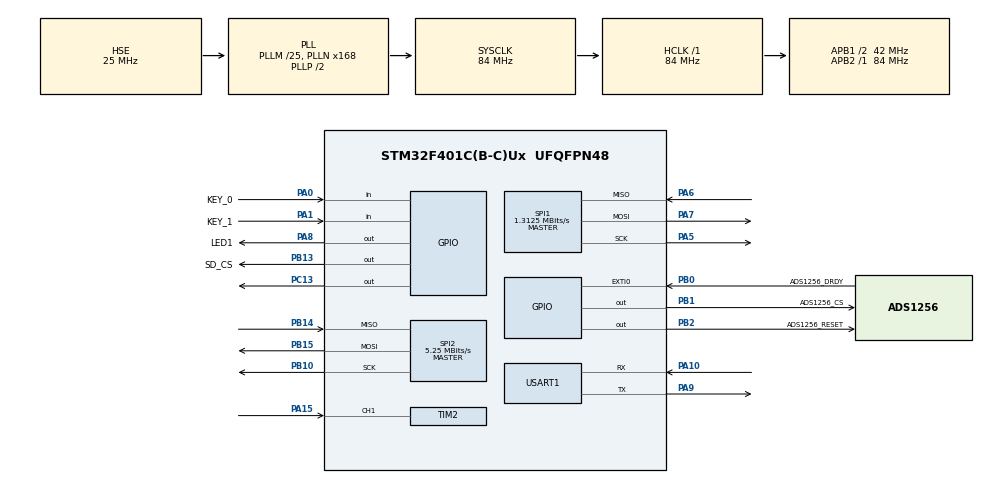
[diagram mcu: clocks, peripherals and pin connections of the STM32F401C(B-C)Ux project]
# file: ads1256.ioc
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FATFS._USE_LABEL=1
FATFS._USE_LFN=3
Mcu.Family=STM32F4
Mcu.Name=STM32F401C(B-C)Ux
Mcu.Package=UFQFPN48
NVIC.EXTI0_IRQn=true\:0\:0\:false\:false\:true\:true\:true\:true
NVIC.PriorityGroup=NVIC_PRIORITYGROUP_4
NVIC.SPI1_IRQn=true\:0\:0\:false\:false\:true\:true\:true\:true
NVIC.TIM1_TRG_COM_TIM11_IRQn=true\:0\:0\:false\:false\:true\:true\:true\:true
NVIC.TIM2_IRQn=true\:0\:0\:false\:false\:true\:true\:true\:true
PA0-WKUP.GPIO_Label=KEY_0
PA0-WKUP.GPIO_PuPd=GPIO_PULLUP
PA0-WKUP.Signal=GPIO_Input
PA1.GPIO_Label=KEY_1
PA1.GPIO_PuPd=GPIO_PULLUP
PA1.Signal=GPIO_Input
PA10.Mode=Asynchronous
PA10.Signal=USART1_RX
PA15.Signal=S_TIM2_CH1_ETR
PA5.Mode=Full_Duplex_Master
PA5.Signal=SPI1_SCK
PA6.Mode=Full_Duplex_Master
PA6.Signal=SPI1_MISO
PA7.Mode=Full_Duplex_Master
PA7.Signal=SPI1_MOSI
PA8.GPIO_Label=LED1
PA8.Signal=GPIO_Output
PA9.Mode=Asynchronous
PA9.Signal=USART1_TX
PB0.GPIO_Label=ADS1256_DRDY
PB0.GPIO_ModeDefaultEXTI=GPIO_MODE_IT_FALLING
PB0.GPIO_PuPd=GPIO_PULLUP
PB0.Signal=GPXTI0
PB1.GPIO_Label=ADS1256_CS
PB1.Signal=GPIO_Output
PB10.Mode=Full_Duplex_Master
PB10.Signal=SPI2_SCK
PB13.GPIO_Label=SD_CS
PB13.Signal=GPIO_Output
PB14.Mode=Full_Duplex_Master
PB14.Signal=SPI2_MISO
PB15.Mode=Full_Duplex_Master
PB15.Signal=SPI2_MOSI
PB2.GPIO_Label=ADS1256_RESET
PB2.Signal=GPIO_Output
PC13-ANTI_TAMP.Signal=GPIO_Output
PH0\ -\ OSC_IN.Mode=HSE-External-Oscillator
PH0\ -\ OSC_IN.Signal=RCC_OSC_IN
PH1\ -\ OSC_OUT.Mode=HSE-External-Oscillator
PH1\ -\ OSC_OUT.Signal=RCC_OSC_OUT
ProjectManager.HeapSize=0x200
ProjectManager.StackSize=0x1400
ProjectManager.TargetToolchain=STM32CubeIDE
RCC.48MHZClocksFreq_Value=42000000
RCC.AHBFreq_Value=84000000
RCC.APB1CLKDivider=RCC_HCLK_DIV2
RCC.APB1Freq_Value=42000000
RCC.APB1TimFreq_Value=84000000
RCC.APB2Freq_Value=84000000
RCC.APB2TimFreq_Value=84000000
RCC.CortexFreq_Value=84000000
RCC.HCLKFreq_Value=84000000
RCC.HSE_VALUE=25000000
RCC.HSI_VALUE=16000000
RCC.LSE_VALUE=32768
RCC.PLLM=25
RCC.PLLN=168
RCC.PLLSourceVirtual=RCC_PLLSOURCE_HSE
RCC.SYSCLKFreq_VALUE=84000000
RCC.SYSCLKSource=RCC_SYSCLKSOURCE_PLLCLK
RCC.VCOOutputFreq_Value=168000000
SH.S_TIM2_CH1_ETR.0=TIM2_CH1,TriggerSource_TI1FP1
SH.S_TIM2_CH1_ETR.1=TIM2_CH1,Input_Capture1_from_TI1
SPI1.BaudRatePrescaler=SPI_BAUDRATEPRESCALER_64
SPI1.CLKPhase=SPI_PHASE_2EDGE
SPI1.CalculateBaudRate=1.3125 MBits/s
SPI1.Direction=SPI_DIRECTION_2LINES
SPI1.Mode=SPI_MODE_MASTER
SPI1.VirtualType=VM_MASTER
SPI2.BaudRatePrescaler=SPI_BAUDRATEPRESCALER_8
SPI2.CLKPhase=SPI_PHASE_1EDGE
SPI2.CLKPolarity=SPI_POLARITY_LOW
SPI2.CalculateBaudRate=5.25 MBits/s
SPI2.Direction=SPI_DIRECTION_2LINES
SPI2.Mode=SPI_MODE_MASTER
SPI2.VirtualType=VM_MASTER
TIM1.AutoReloadPreload=TIM_AUTORELOAD_PRELOAD_ENABLE
TIM1.Period=1000-1
TIM1.Prescaler=83
TIM11.AutoReloadPreload=TIM_AUTORELOAD_PRELOAD_ENABLE
TIM11.Period=999
TIM11.Prescaler=83
TIM2.AutoReloadPreload=TIM_AUTORELOAD_PRELOAD_ENABLE
TIM2.Channel-Input_Capture1_from_TI1=TIM_CHANNEL_1
TIM2.Channel-Input_Capture2_from_TI1_63=TIM_CHANNEL_2
TIM2.ICFilter_CH1=10
TIM2.ICPolarity_CH1=TIM_INPUTCHANNELPOLARITY_RISING
TIM2.ICPolarity_CH2=TIM_INPUTCHANNELPOLARITY_FALLING
TIM2.Period=65535
TIM2.Prescaler=83
TIM3.Period=999
TIM3.TIM_MasterOutputTrigger=TIM_TRGO_UPDATE
USART1.VirtualMode=VM_ASYNC
VP_FATFS_VS_Generic.Mode=User_defined
VP_TIM11_VS_ClockSourceINT.Mode=Enable_Timer
VP_TIM1_VS_ClockSourceINT.Mode=Internal
VP_TIM2_VS_ClockSourceINT.Mode=Internal
VP_TIM2_VS_ControllerModeReset.Mode=Reset Mode
VP_TIM2_VS_indirect_ch1.Mode=Input_Capture2_from_TI1_63
VP_TIM3_VS_ClockSourceINT.Mode=Internal
board=custom

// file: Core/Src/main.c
/* USER CODE BEGIN Header */
/**
  ******************************************************************************
  * @file           : main.c
  * @brief          : Main program body
  ******************************************************************************
  * @attention
  *
  * Copyright (c) 2025 STMicroelectronics.
  * All rights reserved.
  *
  * This software is licensed under terms that can be found in the LICENSE file
  * in the root directory of this software component.
  * If no LICENSE file comes with this software, it is provided AS-IS.
  *
  ******************************************************************************
  */
/* USER CODE END Header */
#include "main.h"
#include "fatfs.h"
#include "spi.h"
#include "tim.h"
#include "usart.h"
#include "gpio.h"

/* USER CODE BEGIN Includes */
#include "../../usr/app_main.h"
/* USER CODE END Includes */

void SystemClock_Config(void);

int main(void)
{

  /* MCU Configuration--------------------------------------------------------*/

  /* Reset of all peripherals, Initializes the Flash interface and the Systick. */
  HAL_Init();

  /* Configure the system clock */
  SystemClock_Config();

  /* Initialize all configured peripherals */
  MX_GPIO_Init();
  MX_SPI1_Init();
  MX_USART1_UART_Init();
  MX_TIM11_Init();
  MX_TIM2_Init();
  MX_TIM3_Init();
  MX_TIM1_Init();
  MX_SPI2_Init();
  /* USER CODE BEGIN 2 */
  NVIC_DisableIRQ(EXTI0_IRQn);
  app_main();
  /* USER CODE END 2 */

  /* Infinite loop */
  /* USER CODE BEGIN WHILE */
  while (1)
  {
    HAL_GPIO_TogglePin(GPIOC,GPIO_PIN_13);
    HAL_Delay(1000);
    /* USER CODE END WHILE */

  }
}

void SystemClock_Config(void)
{
  RCC_OscInitTypeDef RCC_OscInitStruct = {0};
  RCC_ClkInitTypeDef RCC_ClkInitStruct = {0};

  /** Configure the main internal regulator output voltage
  */
  __HAL_RCC_PWR_CLK_ENABLE();
  __HAL_PWR_VOLTAGESCALING_CONFIG(PWR_REGULATOR_VOLTAGE_SCALE2);

  /** Initializes the RCC Oscillators according to the specified parameters
  * in the RCC_OscInitTypeDef structure.
  */
  RCC_OscInitStruct.OscillatorType = RCC_OSCILLATORTYPE_HSE;
  RCC_OscInitStruct.HSEState = RCC_HSE_ON;
  RCC_OscInitStruct.PLL.PLLState = RCC_PLL_ON;
  RCC_OscInitStruct.PLL.PLLSource = RCC_PLLSOURCE_HSE;
  RCC_OscInitStruct.PLL.PLLM = 25;
  RCC_OscInitStruct.PLL.PLLN = 168;
  RCC_OscInitStruct.PLL.PLLP = RCC_PLLP_DIV2;
  RCC_OscInitStruct.PLL.PLLQ = 4;
  if (HAL_RCC_OscConfig(&RCC_OscInitStruct) != HAL_OK)
  {
    Error_Handler();
  }

  /** Initializes the CPU, AHB and APB buses clocks
  */
  RCC_ClkInitStruct.ClockType = RCC_CLOCKTYPE_HCLK|RCC_CLOCKTYPE_SYSCLK
                              |RCC_CLOCKTYPE_PCLK1|RCC_CLOCKTYPE_PCLK2;
  RCC_ClkInitStruct.SYSCLKSource = RCC_SYSCLKSOURCE_PLLCLK;
  RCC_ClkInitStruct.AHBCLKDivider = RCC_SYSCLK_DIV1;
  RCC_ClkInitStruct.APB1CLKDivider = RCC_HCLK_DIV2;
  RCC_ClkInitStruct.APB2CLKDivider = RCC_HCLK_DIV1;

  if (HAL_RCC_ClockConfig(&RCC_ClkInitStruct, FLASH_LATENCY_2) != HAL_OK)
  {
    Error_Handler();
  }
}

void Error_Handler(void)
{
  __disable_irq();
  while (1)
  {
  }
}
